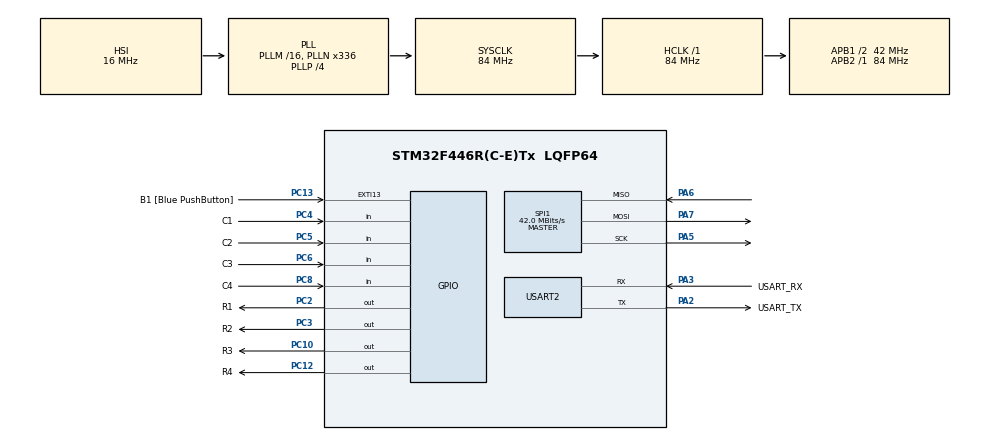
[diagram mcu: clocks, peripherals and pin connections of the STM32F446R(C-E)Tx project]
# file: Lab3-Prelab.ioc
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Dma.Request0=SPI1_TX
Dma.SPI1_TX.0.Direction=DMA_MEMORY_TO_PERIPH
Dma.SPI1_TX.0.FIFOMode=DMA_FIFOMODE_DISABLE
Dma.SPI1_TX.0.Instance=DMA2_Stream3
Dma.SPI1_TX.0.MemDataAlignment=DMA_MDATAALIGN_BYTE
Dma.SPI1_TX.0.MemInc=DMA_MINC_ENABLE
Dma.SPI1_TX.0.Mode=DMA_NORMAL
Dma.SPI1_TX.0.PeriphDataAlignment=DMA_PDATAALIGN_BYTE
Dma.SPI1_TX.0.PeriphInc=DMA_PINC_DISABLE
Dma.SPI1_TX.0.Priority=DMA_PRIORITY_LOW
Mcu.Family=STM32F4
Mcu.Name=STM32F446R(C-E)Tx
Mcu.Package=LQFP64
NVIC.DMA2_Stream3_IRQn=true\:0\:0\:false\:false\:true\:false\:true\:true
NVIC.PriorityGroup=NVIC_PRIORITYGROUP_0
NVIC.SPI1_IRQn=true\:0\:0\:false\:false\:true\:true\:true\:true
PA13.GPIO_Label=TMS
PA13.Mode=Serial_Wire
PA13.Signal=SYS_JTMS-SWDIO
PA14.GPIO_Label=TCK
PA14.Mode=Serial_Wire
PA14.Signal=SYS_JTCK-SWCLK
PA2.GPIO_Label=USART_TX
PA2.Mode=Asynchronous
PA2.Signal=USART2_TX
PA3.GPIO_Label=USART_RX
PA3.Mode=Asynchronous
PA3.Signal=USART2_RX
PA5.Mode=Full_Duplex_Master
PA5.Signal=SPI1_SCK
PA6.Mode=Full_Duplex_Master
PA6.Signal=SPI1_MISO
PA7.Mode=Full_Duplex_Master
PA7.Signal=SPI1_MOSI
PB3.GPIO_Label=SWO
PB3.Signal=SYS_JTDO-SWO
PC10.GPIO_Label=R3
PC10.Signal=GPIO_Output
PC12.GPIO_Label=R4
PC12.Signal=GPIO_Output
PC13.GPIO_Label=B1 [Blue PushButton]
PC13.GPIO_ModeDefaultEXTI=GPIO_MODE_IT_FALLING
PC13.Signal=GPXTI13
PC14-OSC32_IN.Mode=LSE-External-Oscillator
PC14-OSC32_IN.Signal=RCC_OSC32_IN
PC15-OSC32_OUT.Mode=LSE-External-Oscillator
PC15-OSC32_OUT.Signal=RCC_OSC32_OUT
PC2.GPIO_Label=R1
PC2.GPIO_ModeDefaultOutputPP=GPIO_MODE_OUTPUT_OD
PC2.GPIO_PuPd=GPIO_NOPULL
PC2.Signal=GPIO_Output
PC3.GPIO_Label=R2
PC3.GPIO_ModeDefaultOutputPP=GPIO_MODE_OUTPUT_OD
PC3.GPIO_PuPd=GPIO_NOPULL
PC3.Signal=GPIO_Output
PC4.GPIO_Label=C1
PC4.GPIO_PuPd=GPIO_PULLUP
PC4.Signal=GPIO_Input
PC5.GPIO_Label=C2
PC5.GPIO_PuPd=GPIO_PULLUP
PC5.Signal=GPIO_Input
PC6.GPIO_Label=C3
PC6.GPIO_PuPd=GPIO_PULLUP
PC6.Signal=GPIO_Input
PC8.GPIO_Label=C4
PC8.GPIO_PuPd=GPIO_PULLUP
PC8.Signal=GPIO_Input
PH0-OSC_IN.Mode=HSE-External-Oscillator
PH0-OSC_IN.Signal=RCC_OSC_IN
PH1-OSC_OUT.Mode=HSE-External-Oscillator
PH1-OSC_OUT.Signal=RCC_OSC_OUT
ProjectManager.HeapSize=0x200
ProjectManager.StackSize=0x400
ProjectManager.TargetToolchain=MDK-ARM V5.32
RCC.48MHZClocksFreq_Value=84000000
RCC.AHBFreq_Value=84000000
RCC.APB1CLKDivider=RCC_HCLK_DIV2
RCC.APB1Freq_Value=42000000
RCC.APB1TimFreq_Value=84000000
RCC.APB2Freq_Value=84000000
RCC.APB2TimFreq_Value=84000000
RCC.CortexFreq_Value=84000000
RCC.FLatency-AdvancedSettings=FLASH_LATENCY_2
RCC.HCLKFreq_Value=84000000
RCC.HSE_VALUE=8000000
RCC.HSI_VALUE=16000000
RCC.PLLN=336
RCC.PLLP=RCC_PLLP_DIV4
RCC.SYSCLKFreq_VALUE=84000000
RCC.SYSCLKSource=RCC_SYSCLKSOURCE_PLLCLK
RCC.USBFreq_Value=168000000
RCC.VCOOutputFreq_Value=336000000
SPI1.CalculateBaudRate=42.0 MBits/s
SPI1.Direction=SPI_DIRECTION_2LINES
SPI1.Mode=SPI_MODE_MASTER
SPI1.VirtualType=VM_MASTER
USART2.VirtualMode=VM_ASYNC
board=NUCLEO-F446RE

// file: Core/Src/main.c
/* USER CODE BEGIN Header */
/**
  ******************************************************************************
  * @file           : main.c
  * @brief          : Main program body
  ******************************************************************************
  * @attention
  *
  * Copyright (c) 2024 STMicroelectronics.
  * All rights reserved.
  *
  * This software is licensed under terms that can be found in the LICENSE file
  * in the root directory of this software component.
  * If no LICENSE file comes with this software, it is provided AS-IS.
  *
  ******************************************************************************
  */
/* USER CODE END Header */
#include "main.h"
#include "dma.h"
#include "spi.h"
#include "usart.h"
#include "gpio.h"

/* USER CODE BEGIN PV */
/* USER CODE BEGIN Includes */
#include "ili9341.h"
#include "ili9341_gfx.h"
#include "stdio.h"

int fputc(int ch, FILE *f)
{
	HAL_UART_Transmit(&huart2, (uint8_t *)&ch, 1, 0xFFFF);
	return ch;
}

/* USER CODE END Includes */
Е
/* USER CODE BEGIN PV */
ili9341_t *_screen;
/* USER CODE END PV */

void SystemClock_Config(void);

int hour = 0;
int min = 0;
int sec = 0;
int milli = 0;
int row = 0;
int column;
volatile int token = 1;
volatile int keyToken = -1;

void selectRow (int r)
{
	if (r == 0) HAL_GPIO_WritePin(R1_GPIO_Port, R1_Pin, GPIO_PIN_RESET);
	else HAL_GPIO_WritePin(R1_GPIO_Port, R1_Pin, GPIO_PIN_SET);
	if (r == 1) HAL_GPIO_WritePin(R2_GPIO_Port, R2_Pin, GPIO_PIN_RESET);
	else HAL_GPIO_WritePin(R2_GPIO_Port, R2_Pin, GPIO_PIN_SET);
	if (r == 2) HAL_GPIO_WritePin(R3_GPIO_Port, R3_Pin, GPIO_PIN_RESET);
	else HAL_GPIO_WritePin(R3_GPIO_Port, R3_Pin, GPIO_PIN_SET);
	if (r == 3) HAL_GPIO_WritePin(R4_GPIO_Port, R4_Pin, GPIO_PIN_RESET);
	else HAL_GPIO_WritePin(R4_GPIO_Port, R4_Pin, GPIO_PIN_SET);
}

int readCol()
{
	int result = 0;
	if (HAL_GPIO_ReadPin(C1_GPIO_Port, C1_Pin) == GPIO_PIN_RESET) result += 1;
	if (HAL_GPIO_ReadPin(C2_GPIO_Port, C2_Pin) == GPIO_PIN_RESET) result += 2;
	if (HAL_GPIO_ReadPin(C3_GPIO_Port, C3_Pin) == GPIO_PIN_RESET) result += 4;
	if (HAL_GPIO_ReadPin(C4_GPIO_Port, C4_Pin) == GPIO_PIN_RESET) result += 8;
	return result;
}

void HAL_SYSTICK_Callback(void)
{
	milli++;
	selectRow(row % 4);
	column = readCol();
	if (column != 0) {
		// TODO: assign keyToken
	}
	row++;

	if (milli < 1000) { return;	}
	milli = 0;
	sec++;
	token = 1;

	if (sec < 60) {return; }
	sec = 0;
	min++;

	if (min < 60) { return; }
	min = 0;
	hour++;

	if (hour < 24) { return; }
	hour = 0;
}

int keyPressed()
{
		int rowPos = 1; //Current row positiom
		int rowValue; //Value read from the current row

		for (rowPos = 1; rowPos <= 4; rowPos++) {
			selectRow(rowPos);
			HAL_Delay(10);
			rowValue = readCol();

			if (rowValue != 0) { // a key is pressed
				int result = 4*(rowPos-1);
				while (!(rowValue & 1)) { // test if bit #0 is false
					result++;
					rowValue >>= 1;
				}
				while (readCol() != 0); // key no more pressed
				return result;
				}
			}
		return -1;
}

int main(void)
{

  HAL_Init();
  SystemClock_Config();

  MX_GPIO_Init();
  MX_DMA_Init();
  MX_USART2_UART_Init();
  MX_SPI1_Init();
	int key;

  while (1)
  {
		while (token == 0);
		token = 0;

		if (keyToken != -1) {
			switch(keyToken) {
				case 1:
					hour++;
					if (hour > 24) {
						hour = 0;
					}
				case 2:
					hour--;
					if (hour < 0) {
						hour = 0;
					}
				case 3:
					min++;
					if (min > 60) {
						min = 0;
					}
				case 4:
					min--;
					if (min < 0) {
						min = 0;
					}
				case 5:
					milli++;
					if (milli > 60) {
						milli = 0;
					}
				case 6:
					milli--;
					if (milli < 0 ) {
						milli = 0;
					}
			}
		}

		char buffer[20] = {0};
		sprintf(buffer, "%2i:%2i:%2i",hour,min,sec);
		ili9341_fill_screen(_screen,ILI9341_BLACK);
		ili9341_text_attr_t time_attr = {&ili9341_font_11x18,
		ILI9341_WHITE, ILI9341_BLACK,0,0};
		ili9341_draw_string(_screen, time_attr,buffer);
  }
}

void SystemClock_Config(void)
{
  RCC_OscInitTypeDef RCC_OscInitStruct = {0};
  RCC_ClkInitTypeDef RCC_ClkInitStruct = {0};

  /** Configure the main internal regulator output voltage
  */
  __HAL_RCC_PWR_CLK_ENABLE();
  __HAL_PWR_VOLTAGESCALING_CONFIG(PWR_REGULATOR_VOLTAGE_SCALE3);

  /** Initializes the RCC Oscillators according to the specified parameters
  * in the RCC_OscInitTypeDef structure.
  */
  RCC_OscInitStruct.OscillatorType = RCC_OSCILLATORTYPE_HSI;
  RCC_OscInitStruct.HSIState = RCC_HSI_ON;
  RCC_OscInitStruct.HSICalibrationValue = RCC_HSICALIBRATION_DEFAULT;
  RCC_OscInitStruct.PLL.PLLState = RCC_PLL_ON;
  RCC_OscInitStruct.PLL.PLLSource = RCC_PLLSOURCE_HSI;
  RCC_OscInitStruct.PLL.PLLM = 16;
  RCC_OscInitStruct.PLL.PLLN = 336;
  RCC_OscInitStruct.PLL.PLLP = RCC_PLLP_DIV4;
  RCC_OscInitStruct.PLL.PLLQ = 2;
  RCC_OscInitStruct.PLL.PLLR = 2;
  if (HAL_RCC_OscConfig(&RCC_OscInitStruct) != HAL_OK)
  {
    Error_Handler();
  }

  /** Initializes the CPU, AHB and APB buses clocks
  */
  RCC_ClkInitStruct.ClockType = RCC_CLOCKTYPE_HCLK|RCC_CLOCKTYPE_SYSCLK
                              |RCC_CLOCKTYPE_PCLK1|RCC_CLOCKTYPE_PCLK2;
  RCC_ClkInitStruct.SYSCLKSource = RCC_SYSCLKSOURCE_PLLCLK;
  RCC_ClkInitStruct.AHBCLKDivider = RCC_SYSCLK_DIV1;
  RCC_ClkInitStruct.APB1CLKDivider = RCC_HCLK_DIV2;
  RCC_ClkInitStruct.APB2CLKDivider = RCC_HCLK_DIV1;

  if (HAL_RCC_ClockConfig(&RCC_ClkInitStruct, FLASH_LATENCY_2) != HAL_OK)
  {
    Error_Handler();
  }
}

void Error_Handler(void)
{
  __disable_irq();
  while (1)
  {
  }
}
